VERSION ""

BS_:
BU_:

// =====================================================
// TX1 / CAN ID 0x110 / 272
// =====================================================
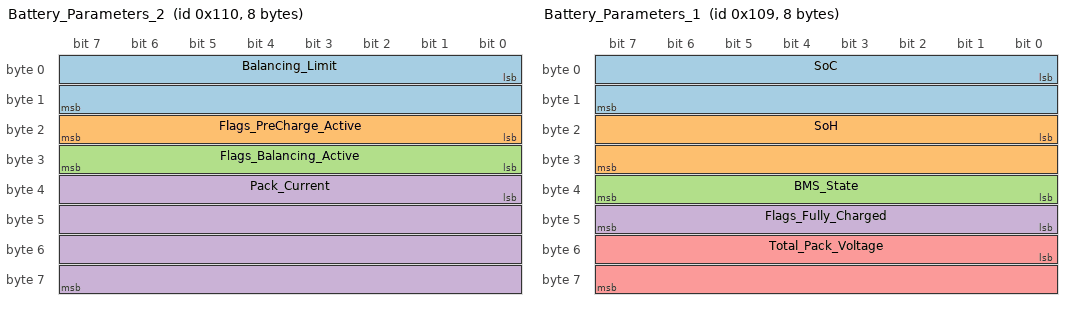
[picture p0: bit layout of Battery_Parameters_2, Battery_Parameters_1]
BO_ 272 Battery_Parameters_2: 8 Vector__XXX
 SG_ Balancing_Limit          : 0|16@1+ (0.1,0) [0|6553.5] "mV" Vector__XXX
 SG_ Flags_PreCharge_Active   : 16|8@1+ (1,0) [0|255] "" Vector__XXX
 SG_ Flags_Balancing_Active   : 24|8@1+ (1,0) [0|255] "" Vector__XXX
 SG_ Pack_Current             : 32|32@1- (1e-005,0) [-21474.8|21474.8] "A" Vector__XXX

// =====================================================
// TX2 / CAN ID 0x109 / 265
// =====================================================
BO_ 265 Battery_Parameters_1: 8 Vector__XXX
 SG_ SoC                 : 0|16@1+ (0.01,0) [0|655.35] "%" Vector__XXX
 SG_ SoH                 : 16|16@1+ (0.01,0) [0|655.35] "%" Vector__XXX
 SG_ BMS_State           : 32|8@1+ (1,0) [0|255] "" Vector__XXX
 SG_ Flags_Fully_Charged : 40|8@1+ (1,0) [0|255] "" Vector__XXX
 SG_ Total_Pack_Voltage  : 48|16@1+ (0.1,0) [0|6553.5] "V" Vector__XXX

// =====================================================
// TX3 / CAN ID 0x112 / 274
// =====================================================
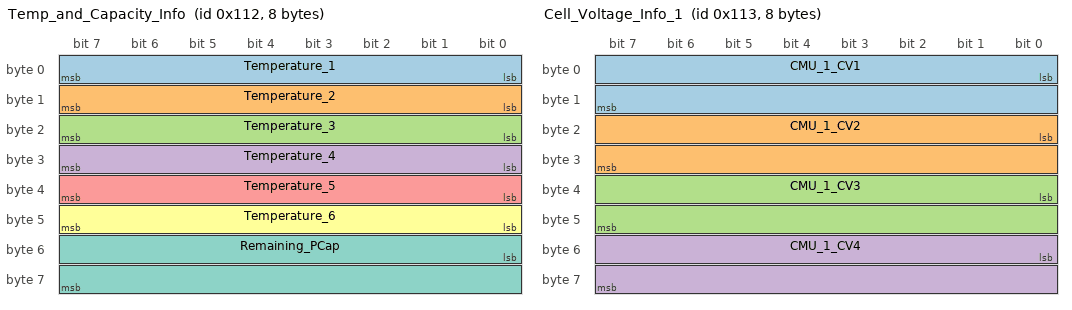
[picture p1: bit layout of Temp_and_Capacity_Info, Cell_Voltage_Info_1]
BO_ 274 Temp_and_Capacity_Info: 8 Vector__XXX
 SG_ Temperature_1  : 0|8@1- (1,0) [-128|127] "degC" Vector__XXX
 SG_ Temperature_2  : 8|8@1- (1,0) [-128|127] "degC" Vector__XXX
 SG_ Temperature_3  : 16|8@1- (1,0) [-128|127] "degC" Vector__XXX
 SG_ Temperature_4  : 24|8@1- (1,0) [-128|127] "degC" Vector__XXX
 SG_ Temperature_5  : 32|8@1- (1,0) [-128|127] "degC" Vector__XXX
 SG_ Temperature_6  : 40|8@1- (1,0) [-128|127] "degC" Vector__XXX
 SG_ Remaining_PCap : 48|16@1+ (0.1,0) [0|6553.5] "Ah" Vector__XXX

// =====================================================
// TX4 / CAN ID 0x113 / 275
// =====================================================
BO_ 275 Cell_Voltage_Info_1: 8 Vector__XXX
 SG_ CMU_1_CV1 : 0|16@1+ (0.1,0) [0|6553.5] "mV" Vector__XXX
 SG_ CMU_1_CV2 : 16|16@1+ (0.1,0) [0|6553.5] "mV" Vector__XXX
 SG_ CMU_1_CV3 : 32|16@1+ (0.1,0) [0|6553.5] "mV" Vector__XXX
 SG_ CMU_1_CV4 : 48|16@1+ (0.1,0) [0|6553.5] "mV" Vector__XXX

// =====================================================
// TX5 / CAN ID 0x114 / 276
// =====================================================
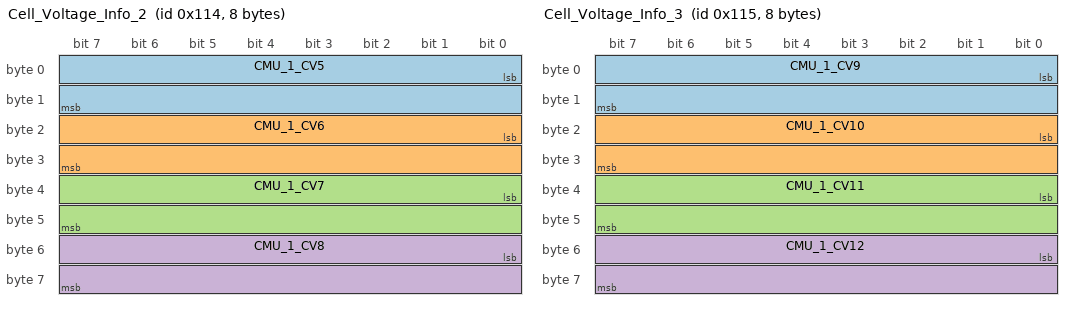
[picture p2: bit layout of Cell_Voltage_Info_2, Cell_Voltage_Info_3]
BO_ 276 Cell_Voltage_Info_2: 8 Vector__XXX
 SG_ CMU_1_CV5 : 0|16@1+ (0.1,0) [0|6553.5] "mV" Vector__XXX
 SG_ CMU_1_CV6 : 16|16@1+ (0.1,0) [0|6553.5] "mV" Vector__XXX
 SG_ CMU_1_CV7 : 32|16@1+ (0.1,0) [0|6553.5] "mV" Vector__XXX
 SG_ CMU_1_CV8 : 48|16@1+ (0.1,0) [0|6553.5] "mV" Vector__XXX

// =====================================================
// TX6 / CAN ID 0x115 / 277
// =====================================================
BO_ 277 Cell_Voltage_Info_3: 8 Vector__XXX
 SG_ CMU_1_CV9  : 0|16@1+ (0.1,0) [0|6553.5] "mV" Vector__XXX
 SG_ CMU_1_CV10 : 16|16@1+ (0.1,0) [0|6553.5] "mV" Vector__XXX
 SG_ CMU_1_CV11 : 32|16@1+ (0.1,0) [0|6553.5] "mV" Vector__XXX
 SG_ CMU_1_CV12 : 48|16@1+ (0.1,0) [0|6553.5] "mV" Vector__XXX

// =====================================================
// TX7 / CAN ID 0x116 / 278
// =====================================================
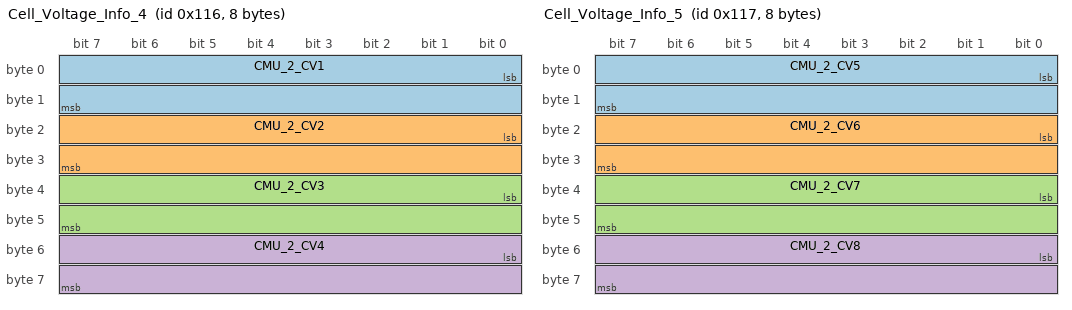
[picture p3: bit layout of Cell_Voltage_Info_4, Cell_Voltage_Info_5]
BO_ 278 Cell_Voltage_Info_4: 8 Vector__XXX
 SG_ CMU_2_CV1 : 0|16@1+ (0.1,0) [0|6553.5] "mV" Vector__XXX
 SG_ CMU_2_CV2 : 16|16@1+ (0.1,0) [0|6553.5] "mV" Vector__XXX
 SG_ CMU_2_CV3 : 32|16@1+ (0.1,0) [0|6553.5] "mV" Vector__XXX
 SG_ CMU_2_CV4 : 48|16@1+ (0.1,0) [0|6553.5] "mV" Vector__XXX

// =====================================================
// TX8 / CAN ID 0x117 / 279
// =====================================================
BO_ 279 Cell_Voltage_Info_5: 8 Vector__XXX
 SG_ CMU_2_CV5 : 0|16@1+ (0.1,0) [0|6553.5] "mV" Vector__XXX
 SG_ CMU_2_CV6 : 16|16@1+ (0.1,0) [0|6553.5] "mV" Vector__XXX
 SG_ CMU_2_CV7 : 32|16@1+ (0.1,0) [0|6553.5] "mV" Vector__XXX
 SG_ CMU_2_CV8 : 48|16@1+ (0.1,0) [0|6553.5] "mV" Vector__XXX

// =====================================================
// TX9 / CAN ID 0x118 / 280
// =====================================================
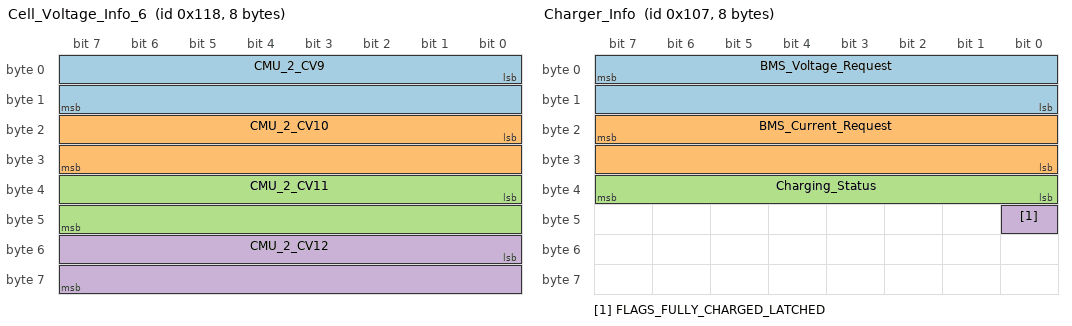
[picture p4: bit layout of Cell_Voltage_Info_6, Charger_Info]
BO_ 280 Cell_Voltage_Info_6: 8 Vector__XXX
 SG_ CMU_2_CV9  : 0|16@1+ (0.1,0) [0|6553.5] "mV" Vector__XXX
 SG_ CMU_2_CV10 : 16|16@1+ (0.1,0) [0|6553.5] "mV" Vector__XXX
 SG_ CMU_2_CV11 : 32|16@1+ (0.1,0) [0|6553.5] "mV" Vector__XXX
 SG_ CMU_2_CV12 : 48|16@1+ (0.1,0) [0|6553.5] "mV" Vector__XXX

// =====================================================
// TX10 / CAN ID 0x107 / 263
// =====================================================
BO_ 263 Charger_Info: 8 Vector__XXX
 SG_ BMS_Voltage_Request : 7|16@0+ (0.1,0) [0|6553.5] "V" Vector__XXX
 SG_ BMS_Current_Request : 23|16@0+ (0.1,0) [0|6553.5] "A" Vector__XXX
 SG_ Charging_Status : 39|8@0+ (1,0) [0|255] "" Vector__XXX
 SG_ FLAGS_FULLY_CHARGED_LATCHED    : 40|1@0+ (1,0) [0|1] "" Vector__XXX

// TX11 / CAN ID 0x12A / 298
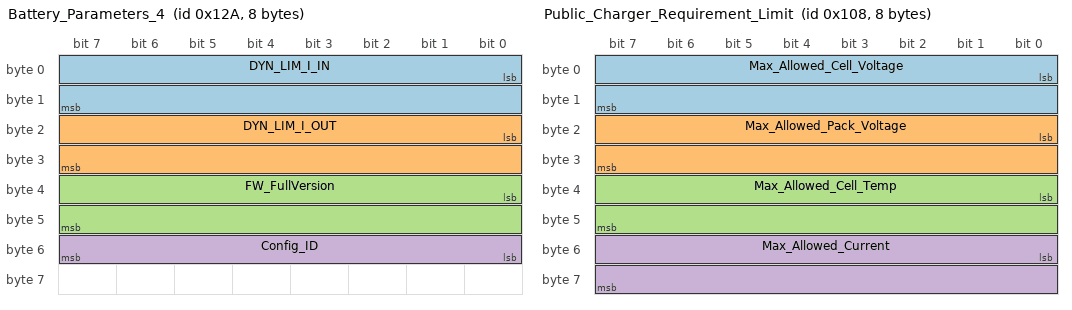
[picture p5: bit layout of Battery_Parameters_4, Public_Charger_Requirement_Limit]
BO_ 298 Battery_Parameters_4: 8 Vector__XXX
 SG_ DYN_LIM_I_IN : 0|16@1+ (0.1,0) [0|6553.5] "A" Vector__XXX
 SG_ DYN_LIM_I_OUT : 16|16@1+ (0.1,0) [0|6553.5] "A" Vector__XXX
 SG_ FW_FullVersion : 32|16@1+ (1,0) [0|65535] "" Vector__XXX
 SG_ Config_ID : 48|8@1+ (1,0) [0|255] "" Vector__XXX

// TX12 / CAN ID 0x108 / 264
BO_ 264 Public_Charger_Requirement_Limit: 8 Vector__XXX
 SG_ Max_Allowed_Cell_Voltage : 0|16@1+ (1,0) [0|65535] "mV" Vector__XXX
 SG_ Max_Allowed_Pack_Voltage : 16|16@1+ (1,0) [0|65535] "V" Vector__XXX
 SG_ Max_Allowed_Cell_Temp : 32|16@1+ (1,0) [0|65535] "C" Vector__XXX
 SG_ Max_Allowed_Current : 48|16@1+ (1,0) [0|65535] "A" Vector__XXX

// =====================================================
// TX13 / CAN ID 0x10A / 266
// =====================================================
BO_ 266 Battery_Parameters_6: 8 Vector__XXX
 SG_ PACK_RESISTANCE_U   : 0|32@1+ (0.1,0) [0|6553.5] "mohm" Vector__XXX
 SG_ RTC_WAKEUP_LATCHED  : 32|8@1+  (1,0) [0|255] "" Vector__XXX

// =====================================================
// TX14 / CAN ID 0x11C / 284
// =====================================================
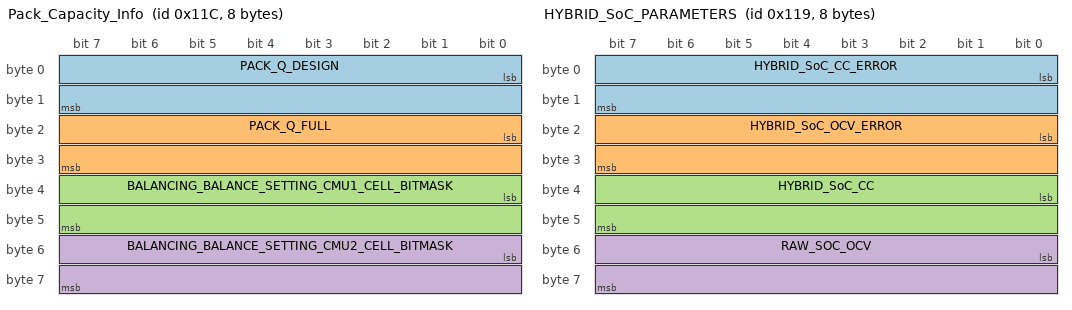
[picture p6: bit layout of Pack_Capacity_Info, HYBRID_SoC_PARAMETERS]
BO_ 284 Pack_Capacity_Info: 8 Vector__XXX
 SG_ PACK_Q_DESIGN : 0|16@1+ (0.1,0) [0|6553.5] "Ah" Vector__XXX
 SG_ PACK_Q_FULL   : 16|16@1+ (0.1,0) [0|6553.5] "Ah" Vector__XXX
 SG_ BALANCING_BALANCE_SETTING_CMU1_CELL_BITMASK : 32|16@1+ (0.1,0) [0|6553.5] "mV" Vector__XXX
 SG_ BALANCING_BALANCE_SETTING_CMU2_CELL_BITMASK : 48|16@1+ (0.1,0) [0|6553.5] "mV" Vector__XXX

// =====================================================
// TX15 / CAN ID 0x119 / 281
// =====================================================
BO_ 281 HYBRID_SoC_PARAMETERS: 8 Vector__XXX
 SG_ HYBRID_SoC_CC_ERROR  : 0|16@1+ (0.1,0) [0|6553.5] "%" Vector__XXX
 SG_ HYBRID_SoC_OCV_ERROR : 16|16@1+ (0.1,0) [0|6553.5] "%" Vector__XXX
 SG_ HYBRID_SoC_CC        : 32|16@1+ (1,0) [0|65535] "%" Vector__XXX
 SG_ RAW_SOC_OCV          : 48|16@1+ (1,0) [0|65535] "%" Vector__XXX

// =====================================================
// TX16 / CAN ID 0x120 / 288
// =====================================================
BO_ 288 TX16: 8 Vector__XXX
SG_ SOC_INTERNAL  : 0|16@1+ (0.01,0) [0|655.35] "%" Vector__XXX
SG_ PACK_CYCLE_NUMBER : 16|16@1+ (1,0) [0|65535] "" Vector__XXX

// =====================================================
// TX17 / CAN ID 0x10B / 267
// =====================================================
BO_ 267 TX17: 8 Vector__XXX
SG_ CHG_TIME_ESTIMATE  : 0|32@1+ (1,0) [0|429496729.5] "s" Vector__XXX
SG_ TOTAL_DISCHARGE_AH : 32|32@1+ (0.1,0) [0|429496729.5] "Ah" Vector__XXX

// =====================================================
// TX18 / CAN ID 0x10C / 268
// =====================================================
BO_ 268 TX18: 8 Vector__XXX
SG_ SOE_WS  : 0|32@1+ (1,0) [0|4294967295] "Ws" Vector__XXX
SG_ SOE_FULL_WS : 32|32@1+ (1,0) [0|4294967295] "Ws" Vector__XXX

// =====================================================
// TX19 / CAN ID 0x10D / 269
// =====================================================
BO_ 269 TX19: 8 Vector__XXX
SG_ P_TOTAL_CHARGE_WH  : 0|32@1+ (0.1,0) [0|429496729.5] "Wh" Vector__XXX
SG_ P_TOTAL_DISCHARGE_WH : 32|32@1+ (0.1,0) [0|429496729.5] "Wh" Vector__XXX

// =====================================================
// Errors
// =====================================================

BO_ 600 Active_Error: 8 Vector__XXX
 SG_ Active_error_Count : 40|16@1+ (1,0) [0|65535] "" Vector__XXX

BO_ 602 Error_Code_1: 8 Vector__XXX
 SG_ Error_Code_1 : 55|16@0+ (1,0) [0|65535] "" Vector__XXX
VAL_ 602 Error_Code_1 2 "ERROR_GENERAL_IOB" 6 "ERROR_GENERAL_NULLPOINT" 7 "ERROR_GENERAL_PAOB" 306 "ERROR_CAN_RX_TIMEOUT" 701 "ERROR_INVALID_TIME_FROM_RTC" 1011 "ERROR_CELL_VDELTA" 1012 "ERROR_CELL_TDELTA" 1100 "ERROR_TEMP_AUX_NO_VALUE" 1116 "ERROR_TEMP_AUX_SHORTED" 1132 "ERROR_TEMP_AUX_OPEN" 1148 "ERROR_TEMP_AUX_MIN_CH01" 1149 "ERROR_TEMP_AUX_MIN_CH02" 1150 "ERROR_TEMP_AUX_MIN_CH03" 1151 "ERROR_TEMP_AUX_MIN_CH04" 1152 "ERROR_TEMP_AUX_MIN_CH05" 1153 "ERROR_TEMP_AUX_MIN_CH06" 1154 "ERROR_TEMP_AUX_MIN_CH07" 1165 "ERROR_TEMP_AUX_MAX_CH01" 1166 "ERROR_TEMP_AUX_MAX_CH02" 1167 "ERROR_TEMP_AUX_MAX_CH03" 1168 "ERROR_TEMP_AUX_MAX_CH04" 1169 "ERROR_TEMP_AUX_MAX_CH05" 1170 "ERROR_TEMP_AUX_MAX_CH06" 1171 "ERROR_TEMP_AUX_MAX_CH08" 2000 "ERROR_SYS_LIM_CELL_V_MIN" 2001 "ERROR_SYS_LIM_CELL_V_MAX" 2004 "ERROR_SYS_LIM_CELL_T_MIN" 2005 "ERROR_SYS_LIM_CELL_T_MAX" 2008 "ERROR_SYS_LIM_PACK_I_IN" 2009 "ERROR_SYS_LIM_PACK_I_OUT" 2010 "ERROR_SYS_LIM_PACK_I_2T" 2011 "ERROR_SYS_CELL_V_NO_VALUE" 2012 "ERROR_SYS_CELL_T_NO_VALUE" 2013 "EROR_SYS_CELL_T_SHORTED" 2014 "ERROR_SYS_CELL_T_OPEN" 2015 "ERROR_SYS_CMU_PCB_T_NO_VALUE" 2016 "ERROR_SYS_CMU_PCB_T_SHORTED" 2017 "ERROR_SYS_CMU_PCB_T_OPEN" 2021 "ERROR_SYS_FB_LOAD_NEG_MISSING" 2022 "ERROR_SYS_FB_LOAD_POS_MISSING" 2023 "ERROR_SYS_FB_PRE_CHARGE_MISSING" 2024 "ERROR_SYS_FB_CHG_NEG_MISSING" 2025 "ERROR_SYS_FB_LOAD_NEG_WELDED" 2026 "ERROR_SYS_FB_LOAD_POS_WELDED" 2027 "ERROR_SYS_FB_PRE_CHARGE_WELDED" 2028 "ERROR_SYS_FB_CHG_NEG_WELDED" 2031 "ERROR_SYS_CONTACTOR_RETRIES" 2042 "ERROR_SYS_LIM_CHG_I_OVER_UNDER" 2048 "ERROR_SYS_OPEN_WIRE" 2050 "ERROR_SYS_ESTOP" 2051 "CONTACTOR_PRE_CHARGE_OPEN" 2052 "CONTACTOR_PRE_CHARGE_SHORT" 2053 "CONTACTOR_POS_OPEN" 2054 "CONTACTOR_SHORT" 2055 "CONTACTOR_PRE_CHARGE_TIMEOUT" 2056 "RESISTANCE_TOO_HIGH" 2057 "DUPLICATE_NODE_ID" 2058 "MISCHARGE" 2059 "MISLOAD" 2062 "CHARGE_NO_RESPONSE" 2063 "ERROR_READY_CURRENT_HIGH" 2080 "AFE_MEASUREMENT_ERROR" 2081 "ERROR_AFE_SM";

BO_ 603 Error_Code_2: 8 Vector__XXX
 SG_ Error_Code_2 : 55|16@0+ (1,0) [0|65535] "" Vector__XXX
VAL_ 603 Error_Code_2 2 "ERROR_GENERAL_IOB" 6 "ERROR_GENERAL_NULLPOINT" 7 "ERROR_GENERAL_PAOB" 306 "ERROR_CAN_RX_TIMEOUT" 701 "ERROR_INVALID_TIME_FROM_RTC" 1011 "ERROR_CELL_VDELTA" 1012 "ERROR_CELL_TDELTA" 1100 "ERROR_TEMP_AUX_NO_VALUE" 1116 "ERROR_TEMP_AUX_SHORTED" 1132 "ERROR_TEMP_AUX_OPEN" 1148 "ERROR_TEMP_AUX_MIN_CH01" 1149 "ERROR_TEMP_AUX_MIN_CH02" 1150 "ERROR_TEMP_AUX_MIN_CH03" 1151 "ERROR_TEMP_AUX_MIN_CH04" 1152 "ERROR_TEMP_AUX_MIN_CH05" 1153 "ERROR_TEMP_AUX_MIN_CH06" 1154 "ERROR_TEMP_AUX_MIN_CH07" 1165 "ERROR_TEMP_AUX_MAX_CH01" 1166 "ERROR_TEMP_AUX_MAX_CH02" 1167 "ERROR_TEMP_AUX_MAX_CH03" 1168 "ERROR_TEMP_AUX_MAX_CH04" 1169 "ERROR_TEMP_AUX_MAX_CH05" 1170 "ERROR_TEMP_AUX_MAX_CH06" 1171 "ERROR_TEMP_AUX_MAX_CH08" 2000 "ERROR_SYS_LIM_CELL_V_MIN" 2001 "ERROR_SYS_LIM_CELL_V_MAX" 2004 "ERROR_SYS_LIM_CELL_T_MIN" 2005 "ERROR_SYS_LIM_CELL_T_MAX" 2008 "ERROR_SYS_LIM_PACK_I_IN" 2009 "ERROR_SYS_LIM_PACK_I_OUT" 2010 "ERROR_SYS_LIM_PACK_I_2T" 2011 "ERROR_SYS_CELL_V_NO_VALUE" 2012 "ERROR_SYS_CELL_T_NO_VALUE" 2013 "EROR_SYS_CELL_T_SHORTED" 2014 "ERROR_SYS_CELL_T_OPEN" 2015 "ERROR_SYS_CMU_PCB_T_NO_VALUE" 2016 "ERROR_SYS_CMU_PCB_T_SHORTED" 2017 "ERROR_SYS_CMU_PCB_T_OPEN" 2021 "ERROR_SYS_FB_LOAD_NEG_MISSING" 2022 "ERROR_SYS_FB_LOAD_POS_MISSING" 2023 "ERROR_SYS_FB_PRE_CHARGE_MISSING" 2024 "ERROR_SYS_FB_CHG_NEG_MISSING" 2025 "ERROR_SYS_FB_LOAD_NEG_WELDED" 2026 "ERROR_SYS_FB_LOAD_POS_WELDED" 2027 "ERROR_SYS_FB_PRE_CHARGE_WELDED" 2028 "ERROR_SYS_FB_CHG_NEG_WELDED" 2031 "ERROR_SYS_CONTACTOR_RETRIES" 2042 "ERROR_SYS_LIM_CHG_I_OVER_UNDER" 2048 "ERROR_SYS_OPEN_WIRE" 2050 "ERROR_SYS_ESTOP" 2051 "CONTACTOR_PRE_CHARGE_OPEN" 2052 "CONTACTOR_PRE_CHARGE_SHORT" 2053 "CONTACTOR_POS_OPEN" 2054 "CONTACTOR_SHORT" 2055 "CONTACTOR_PRE_CHARGE_TIMEOUT" 2056 "RESISTANCE_TOO_HIGH" 2057 "DUPLICATE_NODE_ID" 2058 "MISCHARGE" 2059 "MISLOAD" 2062 "CHARGE_NO_RESPONSE" 2063 "ERROR_READY_CURRENT_HIGH" 2080 "AFE_MEASUREMENT_ERROR" 2081 "ERROR_AFE_SM";

BO_ 604 Error_Code_3: 8 Vector__XXX
 SG_ Error_Code_3 : 55|16@0+ (1,0) [0|65535] "" Vector__XXX
VAL_ 604 Error_Code_3 2 "ERROR_GENERAL_IOB" 6 "ERROR_GENERAL_NULLPOINT" 7 "ERROR_GENERAL_PAOB" 306 "ERROR_CAN_RX_TIMEOUT" 701 "ERROR_INVALID_TIME_FROM_RTC" 1011 "ERROR_CELL_VDELTA" 1012 "ERROR_CELL_TDELTA" 1100 "ERROR_TEMP_AUX_NO_VALUE" 1116 "ERROR_TEMP_AUX_SHORTED" 1132 "ERROR_TEMP_AUX_OPEN" 1148 "ERROR_TEMP_AUX_MIN_CH01" 1149 "ERROR_TEMP_AUX_MIN_CH02" 1150 "ERROR_TEMP_AUX_MIN_CH03" 1151 "ERROR_TEMP_AUX_MIN_CH04" 1152 "ERROR_TEMP_AUX_MIN_CH05" 1153 "ERROR_TEMP_AUX_MIN_CH06" 1154 "ERROR_TEMP_AUX_MIN_CH07" 1165 "ERROR_TEMP_AUX_MAX_CH01" 1166 "ERROR_TEMP_AUX_MAX_CH02" 1167 "ERROR_TEMP_AUX_MAX_CH03" 1168 "ERROR_TEMP_AUX_MAX_CH04" 1169 "ERROR_TEMP_AUX_MAX_CH05" 1170 "ERROR_TEMP_AUX_MAX_CH06" 1171 "ERROR_TEMP_AUX_MAX_CH08" 2000 "ERROR_SYS_LIM_CELL_V_MIN" 2001 "ERROR_SYS_LIM_CELL_V_MAX" 2004 "ERROR_SYS_LIM_CELL_T_MIN" 2005 "ERROR_SYS_LIM_CELL_T_MAX" 2008 "ERROR_SYS_LIM_PACK_I_IN" 2009 "ERROR_SYS_LIM_PACK_I_OUT" 2010 "ERROR_SYS_LIM_PACK_I_2T" 2011 "ERROR_SYS_CELL_V_NO_VALUE" 2012 "ERROR_SYS_CELL_T_NO_VALUE" 2013 "EROR_SYS_CELL_T_SHORTED" 2014 "ERROR_SYS_CELL_T_OPEN" 2015 "ERROR_SYS_CMU_PCB_T_NO_VALUE" 2016 "ERROR_SYS_CMU_PCB_T_SHORTED" 2017 "ERROR_SYS_CMU_PCB_T_OPEN" 2021 "ERROR_SYS_FB_LOAD_NEG_MISSING" 2022 "ERROR_SYS_FB_LOAD_POS_MISSING" 2023 "ERROR_SYS_FB_PRE_CHARGE_MISSING" 2024 "ERROR_SYS_FB_CHG_NEG_MISSING" 2025 "ERROR_SYS_FB_LOAD_NEG_WELDED" 2026 "ERROR_SYS_FB_LOAD_POS_WELDED" 2027 "ERROR_SYS_FB_PRE_CHARGE_WELDED" 2028 "ERROR_SYS_FB_CHG_NEG_WELDED" 2031 "ERROR_SYS_CONTACTOR_RETRIES" 2042 "ERROR_SYS_LIM_CHG_I_OVER_UNDER" 2048 "ERROR_SYS_OPEN_WIRE" 2050 "ERROR_SYS_ESTOP" 2051 "CONTACTOR_PRE_CHARGE_OPEN" 2052 "CONTACTOR_PRE_CHARGE_SHORT" 2053 "CONTACTOR_POS_OPEN" 2054 "CONTACTOR_SHORT" 2055 "CONTACTOR_PRE_CHARGE_TIMEOUT" 2056 "RESISTANCE_TOO_HIGH" 2057 "DUPLICATE_NODE_ID" 2058 "MISCHARGE" 2059 "MISLOAD" 2062 "CHARGE_NO_RESPONSE" 2063 "ERROR_READY_CURRENT_HIGH" 2080 "AFE_MEASUREMENT_ERROR" 2081 "ERROR_AFE_SM";

BO_ 605 Error_Code_4: 8 Vector__XXX
 SG_ Error_Code_4 : 55|16@0+ (1,0) [0|65535] "" Vector__XXX
VAL_ 605 Error_Code_4 2 "ERROR_GENERAL_IOB" 6 "ERROR_GENERAL_NULLPOINT" 7 "ERROR_GENERAL_PAOB" 306 "ERROR_CAN_RX_TIMEOUT" 701 "ERROR_INVALID_TIME_FROM_RTC" 1011 "ERROR_CELL_VDELTA" 1012 "ERROR_CELL_TDELTA" 1100 "ERROR_TEMP_AUX_NO_VALUE" 1116 "ERROR_TEMP_AUX_SHORTED" 1132 "ERROR_TEMP_AUX_OPEN" 1148 "ERROR_TEMP_AUX_MIN_CH01" 1149 "ERROR_TEMP_AUX_MIN_CH02" 1150 "ERROR_TEMP_AUX_MIN_CH03" 1151 "ERROR_TEMP_AUX_MIN_CH04" 1152 "ERROR_TEMP_AUX_MIN_CH05" 1153 "ERROR_TEMP_AUX_MIN_CH06" 1154 "ERROR_TEMP_AUX_MIN_CH07" 1165 "ERROR_TEMP_AUX_MAX_CH01" 1166 "ERROR_TEMP_AUX_MAX_CH02" 1167 "ERROR_TEMP_AUX_MAX_CH03" 1168 "ERROR_TEMP_AUX_MAX_CH04" 1169 "ERROR_TEMP_AUX_MAX_CH05" 1170 "ERROR_TEMP_AUX_MAX_CH06" 1171 "ERROR_TEMP_AUX_MAX_CH08" 2000 "ERROR_SYS_LIM_CELL_V_MIN" 2001 "ERROR_SYS_LIM_CELL_V_MAX" 2004 "ERROR_SYS_LIM_CELL_T_MIN" 2005 "ERROR_SYS_LIM_CELL_T_MAX" 2008 "ERROR_SYS_LIM_PACK_I_IN" 2009 "ERROR_SYS_LIM_PACK_I_OUT" 2010 "ERROR_SYS_LIM_PACK_I_2T" 2011 "ERROR_SYS_CELL_V_NO_VALUE" 2012 "ERROR_SYS_CELL_T_NO_VALUE" 2013 "EROR_SYS_CELL_T_SHORTED" 2014 "ERROR_SYS_CELL_T_OPEN" 2015 "ERROR_SYS_CMU_PCB_T_NO_VALUE" 2016 "ERROR_SYS_CMU_PCB_T_SHORTED" 2017 "ERROR_SYS_CMU_PCB_T_OPEN" 2021 "ERROR_SYS_FB_LOAD_NEG_MISSING" 2022 "ERROR_SYS_FB_LOAD_POS_MISSING" 2023 "ERROR_SYS_FB_PRE_CHARGE_MISSING" 2024 "ERROR_SYS_FB_CHG_NEG_MISSING" 2025 "ERROR_SYS_FB_LOAD_NEG_WELDED" 2026 "ERROR_SYS_FB_LOAD_POS_WELDED" 2027 "ERROR_SYS_FB_PRE_CHARGE_WELDED" 2028 "ERROR_SYS_FB_CHG_NEG_WELDED" 2031 "ERROR_SYS_CONTACTOR_RETRIES" 2042 "ERROR_SYS_LIM_CHG_I_OVER_UNDER" 2048 "ERROR_SYS_OPEN_WIRE" 2050 "ERROR_SYS_ESTOP" 2051 "CONTACTOR_PRE_CHARGE_OPEN" 2052 "CONTACTOR_PRE_CHARGE_SHORT" 2053 "CONTACTOR_POS_OPEN" 2054 "CONTACTOR_SHORT" 2055 "CONTACTOR_PRE_CHARGE_TIMEOUT" 2056 "RESISTANCE_TOO_HIGH" 2057 "DUPLICATE_NODE_ID" 2058 "MISCHARGE" 2059 "MISLOAD" 2062 "CHARGE_NO_RESPONSE" 2063 "ERROR_READY_CURRENT_HIGH" 2080 "AFE_MEASUREMENT_ERROR" 2081 "ERROR_AFE_SM";

BO_ 606 Error_Code_5: 8 Vector__XXX
 SG_ Error_Code_5 : 55|16@0+ (1,0) [0|65535] "" Vector__XXX
VAL_ 606 Error_Code_5 2 "ERROR_GENERAL_IOB" 6 "ERROR_GENERAL_NULLPOINT" 7 "ERROR_GENERAL_PAOB" 306 "ERROR_CAN_RX_TIMEOUT" 701 "ERROR_INVALID_TIME_FROM_RTC" 1011 "ERROR_CELL_VDELTA" 1012 "ERROR_CELL_TDELTA" 1100 "ERROR_TEMP_AUX_NO_VALUE" 1116 "ERROR_TEMP_AUX_SHORTED" 1132 "ERROR_TEMP_AUX_OPEN" 1148 "ERROR_TEMP_AUX_MIN_CH01" 1149 "ERROR_TEMP_AUX_MIN_CH02" 1150 "ERROR_TEMP_AUX_MIN_CH03" 1151 "ERROR_TEMP_AUX_MIN_CH04" 1152 "ERROR_TEMP_AUX_MIN_CH05" 1153 "ERROR_TEMP_AUX_MIN_CH06" 1154 "ERROR_TEMP_AUX_MIN_CH07" 1165 "ERROR_TEMP_AUX_MAX_CH01" 1166 "ERROR_TEMP_AUX_MAX_CH02" 1167 "ERROR_TEMP_AUX_MAX_CH03" 1168 "ERROR_TEMP_AUX_MAX_CH04" 1169 "ERROR_TEMP_AUX_MAX_CH05" 1170 "ERROR_TEMP_AUX_MAX_CH06" 1171 "ERROR_TEMP_AUX_MAX_CH08" 2000 "ERROR_SYS_LIM_CELL_V_MIN" 2001 "ERROR_SYS_LIM_CELL_V_MAX" 2004 "ERROR_SYS_LIM_CELL_T_MIN" 2005 "ERROR_SYS_LIM_CELL_T_MAX" 2008 "ERROR_SYS_LIM_PACK_I_IN" 2009 "ERROR_SYS_LIM_PACK_I_OUT" 2010 "ERROR_SYS_LIM_PACK_I_2T" 2011 "ERROR_SYS_CELL_V_NO_VALUE" 2012 "ERROR_SYS_CELL_T_NO_VALUE" 2013 "EROR_SYS_CELL_T_SHORTED" 2014 "ERROR_SYS_CELL_T_OPEN" 2015 "ERROR_SYS_CMU_PCB_T_NO_VALUE" 2016 "ERROR_SYS_CMU_PCB_T_SHORTED" 2017 "ERROR_SYS_CMU_PCB_T_OPEN" 2021 "ERROR_SYS_FB_LOAD_NEG_MISSING" 2022 "ERROR_SYS_FB_LOAD_POS_MISSING" 2023 "ERROR_SYS_FB_PRE_CHARGE_MISSING" 2024 "ERROR_SYS_FB_CHG_NEG_MISSING" 2025 "ERROR_SYS_FB_LOAD_NEG_WELDED" 2026 "ERROR_SYS_FB_LOAD_POS_WELDED" 2027 "ERROR_SYS_FB_PRE_CHARGE_WELDED" 2028 "ERROR_SYS_FB_CHG_NEG_WELDED" 2031 "ERROR_SYS_CONTACTOR_RETRIES" 2042 "ERROR_SYS_LIM_CHG_I_OVER_UNDER" 2048 "ERROR_SYS_OPEN_WIRE" 2050 "ERROR_SYS_ESTOP" 2051 "CONTACTOR_PRE_CHARGE_OPEN" 2052 "CONTACTOR_PRE_CHARGE_SHORT" 2053 "CONTACTOR_POS_OPEN" 2054 "CONTACTOR_SHORT" 2055 "CONTACTOR_PRE_CHARGE_TIMEOUT" 2056 "RESISTANCE_TOO_HIGH" 2057 "DUPLICATE_NODE_ID" 2058 "MISCHARGE" 2059 "MISLOAD" 2062 "CHARGE_NO_RESPONSE" 2063 "ERROR_READY_CURRENT_HIGH" 2080 "AFE_MEASUREMENT_ERROR" 2081 "ERROR_AFE_SM";

BO_ 1026 ODO_TRIP: 8 Vector__XXX
 SG_ ODO  : 0|32@1+ (0.1,0) [0|429496729.5] "km" Vector__XXX

BO_ 1542 AuxVoltage: 8 Vector__XXX
 SG_ AuxVoltage : 15|16@0+ (0.01,0) [0|655.35] "V" Vector__XXX

BO_ 1538 Vehicle_State: 8 Vector__XXX
SG_ gunConnected : 48|8@1- (1,0) [0|0] "" Vector__XXX
SG_ VehicleState : 56|8@1+ (1,0) [0|0] "" Vector__XXX
VAL_ 1538 VehicleState           0 "Off" 1 "Charge" 2 "Drive" 3 "Full Charge" ;

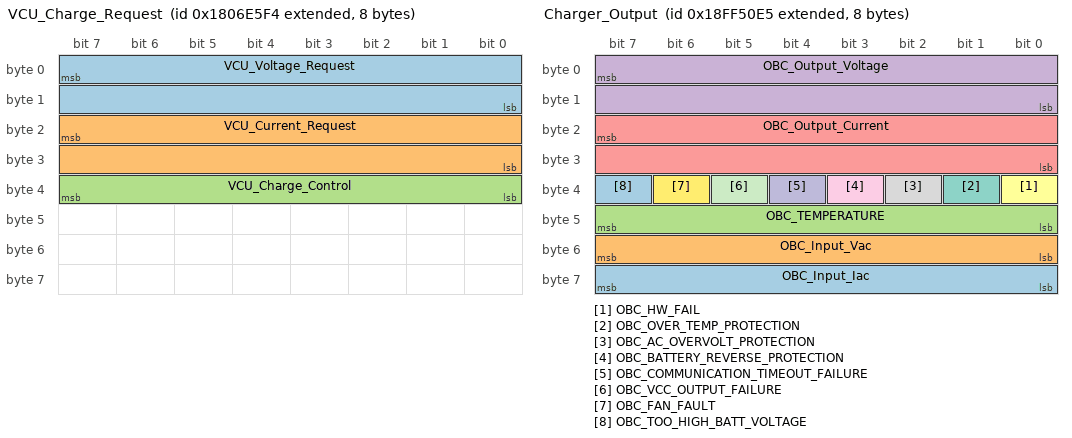
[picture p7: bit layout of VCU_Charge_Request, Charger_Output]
BO_ 2550588916 VCU_Charge_Request: 8 Vector__XXX
 SG_ VCU_Voltage_Request : 7|16@0+ (0.1,0) [0|6553.5] "V" Vector__XXX
 SG_ VCU_Current_Request : 23|16@0+ (0.1,0) [0|6553.5] "A" Vector__XXX
 SG_ VCU_Charge_Control  : 39|8@0+ (1,0) [0|1] "" Vector__XXX

BO_ 2566869221 Charger_Output: 8 Vector__XXX
 SG_ OBC_Input_Iac : 63|8@0+ (0.1,0) [0|25.5] "A" Vector__XXX
 SG_ OBC_Input_Vac : 55|8@0+ (2,0) [0|510] "V" Vector__XXX
 SG_ OBC_TEMPERATURE : 47|8@0+ (1,-100) [-100|155] "°C" Vector__XXX
 SG_ OBC_Output_Voltage : 7|16@0+ (0.1,0) [0|6553.5] "V" Vector__XXX
 SG_ OBC_Output_Current : 23|16@0+ (0.1,0) [0|6553.5] "A" Vector__XXX
 SG_ OBC_HW_FAIL : 32|1@0- (1,0) [0|1] "" Vector__XXX
 SG_ OBC_OVER_TEMP_PROTECTION : 33|1@0- (1,0) [0|1] "" Vector__XXX
 SG_ OBC_AC_OVERVOLT_PROTECTION : 34|1@0- (1,0) [0|1] "" Vector__XXX
 SG_ OBC_BATTERY_REVERSE_PROTECTION : 35|1@0- (1,0) [0|1] "" Vector__XXX
 SG_ OBC_COMMUNICATION_TIMEOUT_FAILURE : 36|1@0- (1,0) [0|1] "" Vector__XXX
 SG_ OBC_VCC_OUTPUT_FAILURE : 37|1@0- (1,0) [0|1] "" Vector__XXX
 SG_ OBC_FAN_FAULT : 38|1@0- (1,0) [0|1] "" Vector__XXX
 SG_ OBC_TOO_HIGH_BATT_VOLTAGE : 39|1@0- (1,0) [0|1] "" Vector__XXX

BO_ 1813 MCU_CAP_RPM: 8 Vector__XXX
 SG_ MCU_BATT_KSI : 40|8@1+ (1,0) [0|255] "V" Vector__XXX
 SG_ MCU_CAP_Volt : 32|8@1+ (1,0) [0|255] "V" Vector__XXX

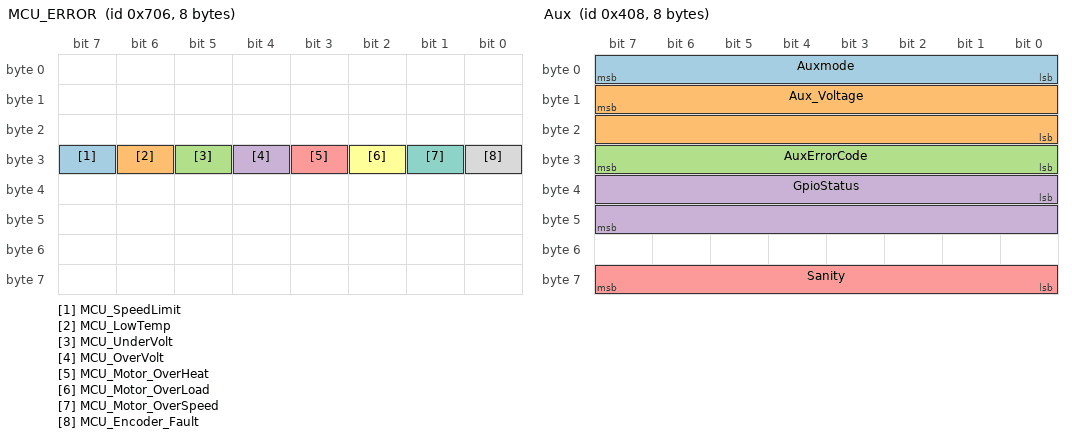
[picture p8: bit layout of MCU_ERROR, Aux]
BO_ 1798 MCU_ERROR: 8 Vector__XXX
 SG_ MCU_SpeedLimit : 31|1@1+ (1,0) [0|1] "" Vector__XXX
 SG_ MCU_LowTemp : 30|1@1+ (1,0) [0|1] "" Vector__XXX
 SG_ MCU_UnderVolt : 29|1@1+ (1,0) [0|1] "" Vector__XXX
 SG_ MCU_OverVolt : 28|1@1+ (1,0) [0|1] "" Vector__XXX
 SG_ MCU_Motor_OverHeat : 27|1@1+ (1,0) [0|1] "" Vector__XXX
 SG_ MCU_Motor_OverLoad : 26|1@1+ (1,0) [0|1] "" Vector__XXX
 SG_ MCU_Motor_OverSpeed : 25|1@1+ (1,0) [0|1] "" Vector__XXX
 SG_ MCU_Encoder_Fault : 24|1@1+ (1,0) [0|1] "" Vector__XXX

BO_ 1571 GPIO_DCDC_OUT : 8 Vector__XXX
 SG_ DCDC_OUT :10|1@1+ (1,0) [0|0] "" Vector__XXX

BO_ 1032 Aux: 8 Vector__XXX
 SG_ Auxmode : 0|8@1+ (1,0) [0|0] "" Vector__XXX
 SG_ Aux_Voltage : 15|16@0+ (0.01,0) [0|0] "" Vector__XXX
 SG_ AuxErrorCode : 24|8@1+ (1,0) [0|0] "" Vector__XXX
 SG_ GpioStatus : 32|16@1+ (1,0) [0|0] "" Vector__XXX
 SG_ Sanity : 56|8@1+ (1,0) [0|0] "" Vector__XXX

BO_ 1776 Reset: 8 Vector__XXX
 SG_ EcuId : 0|8@1+ (1,0) [0|0] "" Vector__XXX
